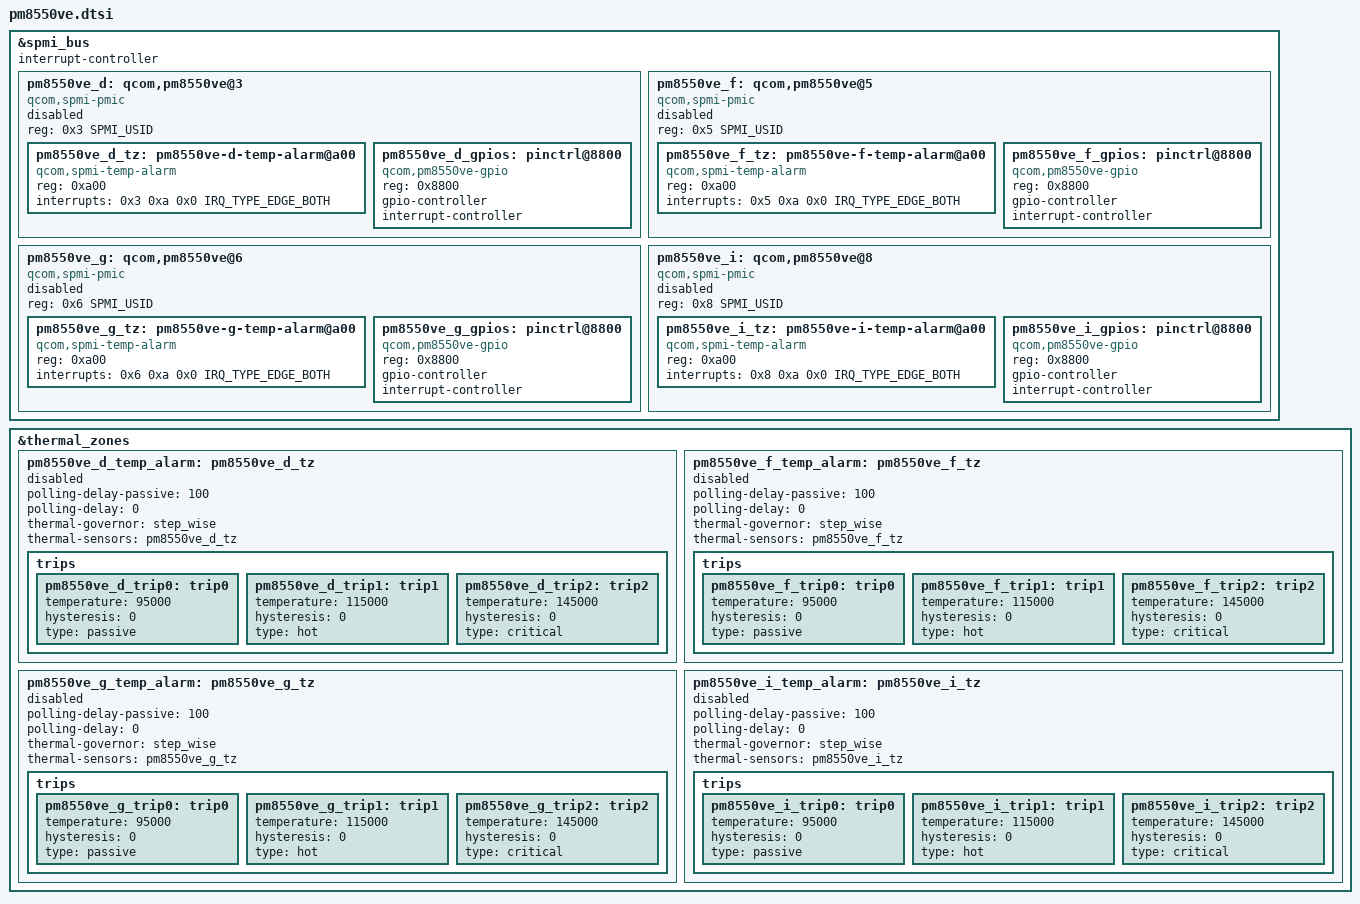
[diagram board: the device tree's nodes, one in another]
// SPDX-License-Identifier: BSD-3-Clause
/*
 * Copyright (c) 2022-2024 Qualcomm Innovation Center, Inc. All rights reserved.
 */

#include <dt-bindings/interrupt-controller/irq.h>
#include <dt-bindings/spmi/spmi.h>

&spmi_bus {
	#address-cells = <2>;
	#size-cells = <0>;
	interrupt-controller;
	#interrupt-cells = <4>;

	pm8550ve_d: qcom,pm8550ve@3 {
		compatible = "qcom,spmi-pmic";
		reg = <0x3 SPMI_USID>;
		#address-cells = <1>;
		#size-cells = <0>;
		status = "disabled";

		pm8550ve_d_tz: pm8550ve-d-temp-alarm@a00 {
			compatible = "qcom,spmi-temp-alarm";
			reg = <0xa00>;
			interrupts = <0x3 0xa 0x0 IRQ_TYPE_EDGE_BOTH>;
			#thermal-sensor-cells = <0>;
		};

		pm8550ve_d_gpios: pinctrl@8800 {
			compatible = "qcom,pm8550ve-gpio";
			reg = <0x8800>;
			gpio-controller;
			#gpio-cells = <2>;
			interrupt-controller;
			#interrupt-cells = <2>;
		};
	};

	pm8550ve_f: qcom,pm8550ve@5 {
		compatible = "qcom,spmi-pmic";
		reg = <0x5 SPMI_USID>;
		#address-cells = <1>;
		#size-cells = <0>;
		status = "disabled";

		pm8550ve_f_tz: pm8550ve-f-temp-alarm@a00 {
			compatible = "qcom,spmi-temp-alarm";
			reg = <0xa00>;
			interrupts = <0x5 0xa 0x0 IRQ_TYPE_EDGE_BOTH>;
			#thermal-sensor-cells = <0>;
		};

		pm8550ve_f_gpios: pinctrl@8800 {
			compatible = "qcom,pm8550ve-gpio";
			reg = <0x8800>;
			gpio-controller;
			#gpio-cells = <2>;
			interrupt-controller;
			#interrupt-cells = <2>;
		};
	};

	pm8550ve_g: qcom,pm8550ve@6 {
		compatible = "qcom,spmi-pmic";
		reg = <0x6 SPMI_USID>;
		#address-cells = <1>;
		#size-cells = <0>;
		status = "disabled";

		pm8550ve_g_tz: pm8550ve-g-temp-alarm@a00 {
			compatible = "qcom,spmi-temp-alarm";
			reg = <0xa00>;
			interrupts = <0x6 0xa 0x0 IRQ_TYPE_EDGE_BOTH>;
			#thermal-sensor-cells = <0>;
		};

		pm8550ve_g_gpios: pinctrl@8800 {
			compatible = "qcom,pm8550ve-gpio";
			reg = <0x8800>;
			gpio-controller;
			#gpio-cells = <2>;
			interrupt-controller;
			#interrupt-cells = <2>;
		};
	};

	pm8550ve_i: qcom,pm8550ve@8 {
		compatible = "qcom,spmi-pmic";
		reg = <0x8 SPMI_USID>;
		#address-cells = <1>;
		#size-cells = <0>;
		status = "disabled";

		pm8550ve_i_tz: pm8550ve-i-temp-alarm@a00 {
			compatible = "qcom,spmi-temp-alarm";
			reg = <0xa00>;
			interrupts = <0x8 0xa 0x0 IRQ_TYPE_EDGE_BOTH>;
			#thermal-sensor-cells = <0>;
		};

		pm8550ve_i_gpios: pinctrl@8800 {
			compatible = "qcom,pm8550ve-gpio";
			reg = <0x8800>;
			gpio-controller;
			#gpio-cells = <2>;
			interrupt-controller;
			#interrupt-cells = <2>;
		};
	};
};

&thermal_zones {
	pm8550ve_d_temp_alarm: pm8550ve_d_tz {
		polling-delay-passive = <100>;
		polling-delay = <0>;
		thermal-governor = "step_wise";
		thermal-sensors = <&pm8550ve_d_tz>;
		status = "disabled";

		trips {
			pm8550ve_d_trip0: trip0 {
				temperature = <95000>;
				hysteresis = <0>;
				type = "passive";
			};

			pm8550ve_d_trip1: trip1 {
				temperature = <115000>;
				hysteresis = <0>;
				type = "hot";
			};

			pm8550ve_d_trip2: trip2 {
				temperature = <145000>;
				hysteresis = <0>;
				type = "critical";
			};
		};
	};

	pm8550ve_f_temp_alarm: pm8550ve_f_tz {
		polling-delay-passive = <100>;
		polling-delay = <0>;
		thermal-governor = "step_wise";
		thermal-sensors = <&pm8550ve_f_tz>;
		status = "disabled";

		trips {
			pm8550ve_f_trip0: trip0 {
				temperature = <95000>;
				hysteresis = <0>;
				type = "passive";
			};

			pm8550ve_f_trip1: trip1 {
				temperature = <115000>;
				hysteresis = <0>;
				type = "hot";
			};

			pm8550ve_f_trip2: trip2 {
				temperature = <145000>;
				hysteresis = <0>;
				type = "critical";
			};
		};
	};

	pm8550ve_g_temp_alarm: pm8550ve_g_tz {
		polling-delay-passive = <100>;
		polling-delay = <0>;
		thermal-governor = "step_wise";
		thermal-sensors = <&pm8550ve_g_tz>;
		status = "disabled";

		trips {
			pm8550ve_g_trip0: trip0 {
				temperature = <95000>;
				hysteresis = <0>;
				type = "passive";
			};

			pm8550ve_g_trip1: trip1 {
				temperature = <115000>;
				hysteresis = <0>;
				type = "hot";
			};

			pm8550ve_g_trip2: trip2 {
				temperature = <145000>;
				hysteresis = <0>;
				type = "critical";
			};
		};
	};

	pm8550ve_i_temp_alarm: pm8550ve_i_tz {
		polling-delay-passive = <100>;
		polling-delay = <0>;
		thermal-governor = "step_wise";
		thermal-sensors = <&pm8550ve_i_tz>;
		status = "disabled";

		trips {
			pm8550ve_i_trip0: trip0 {
				temperature = <95000>;
				hysteresis = <0>;
				type = "passive";
			};

			pm8550ve_i_trip1: trip1 {
				temperature = <115000>;
				hysteresis = <0>;
				type = "hot";
			};

			pm8550ve_i_trip2: trip2 {
				temperature = <145000>;
				hysteresis = <0>;
				type = "critical";
			};
		};
	};
};
